# nrf7140_application register map
Vendor: Nordic Semiconductor; Series: nRF71; File version: 1
CPU: CM33 r0p4, little endian, MPU, FPU, 3 interrupt priority bits, 480 interrupts, 8 SAU regions
Registers are 32-bit, read-write, reset 0x0 unless marked. A register's access mark holds for its fields unless they carry their own. Offsets are from the block's base; [hi:lo] are bit positions; lines under a group give offsets from that group; {n}, {i} and the like mark numbered series.

## GLOBAL_P0_NS — GPIO Port 0
Base 0x4F938000
Same registers: GLOBAL_P1_NS 0x4F938200, GLOBAL_P2_NS 0x4F938400, GLOBAL_P3_NS 0x4F938600, GLOBAL_P5_NS 0x4F938A00, GLOBAL_P6_NS 0x4F938C00, GLOBAL_P8_NS 0x4F939000, GLOBAL_P9_NS 0x4F939200, GLOBAL_P0_S 0x5F938000, GLOBAL_P1_S 0x5F938200, GLOBAL_P2_S 0x5F938400, GLOBAL_P3_S 0x5F938600, GLOBAL_P5_S 0x5F938A00, GLOBAL_P6_S 0x5F938C00, GLOBAL_P8_S 0x5F939000, GLOBAL_P9_S 0x5F939200
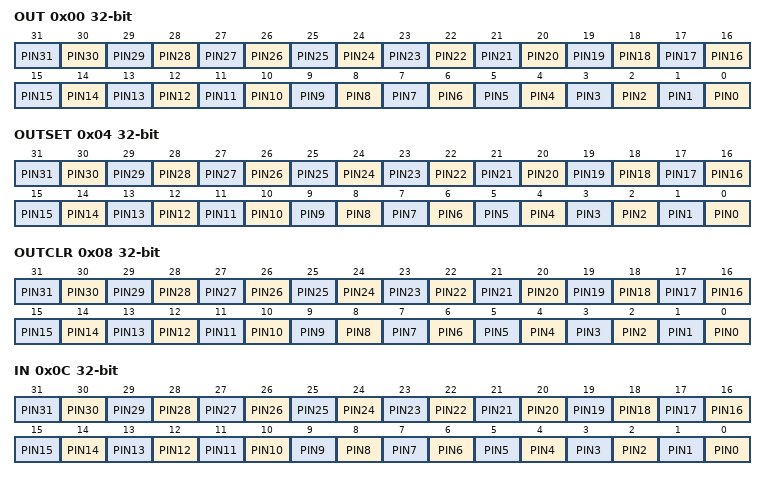
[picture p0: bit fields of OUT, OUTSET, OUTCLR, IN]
0x00 OUT — Write GPIO port
  [all] fields
    0=Low (Pin driver is low); 1=High (Pin driver is high)
  [n] PIN{n} (n=0..31)
0x04 OUTSET write-1-sets — Set individual bits in GPIO port
  [all] fields
    on read: 0=Low (Read: pin driver is low); 1=High (Read: pin driver is high) | on write: 1=Set (Write: writing a '1' sets the pin high; writing a '0' has no effect)
  [n] PIN{n} (n=0..31)
0x08 OUTCLR write-1-clears — Clear individual bits in GPIO port
  [all] fields
    on read: 0=Low (Read: pin driver is low); 1=High (Read: pin driver is high) | on write: 1=Clear (Write: writing a '1' sets the pin low; writing a '0' has no effect)
  [n] PIN{n} (n=0..31)
0x0C IN ro — Read GPIO port
  [all] fields
    0=Low (Pin input is low); 1=High (Pin input is high)
  [n] PIN{n} (n=0..31)
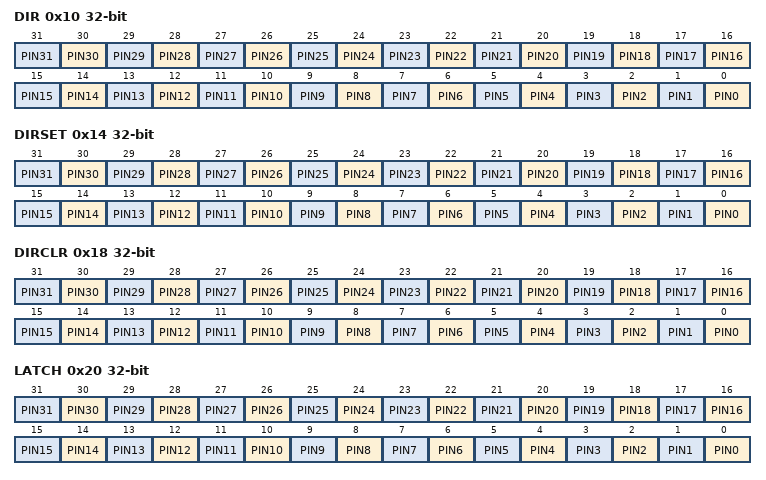
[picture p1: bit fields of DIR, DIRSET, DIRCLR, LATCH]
0x10 DIR — Direction of GPIO pins
  [all] fields
    0=Input (Pin set as input); 1=Output (Pin set as output)
  [n] PIN{n} (n=0..31)
0x14 DIRSET write-1-sets
  [all] fields
    on read: 0=Input (Read: pin set as input); 1=Output (Read: pin set as output) | on write: 1=Set (Write: writing a '1' sets pin to output; writing a '0' has no effect)
  [n] PIN{n} (n=0..31) — Set as output pin {n}
0x18 DIRCLR write-1-clears — DIR clear register
  [all] fields
    on read: 0=Input (Read: pin set as input); 1=Output (Read: pin set as output) | on write: 1=Clear (Write: writing a '1' sets pin to input; writing a '0' has no effect)
  [n] PIN{n} (n=0..31) — Set as input pin {n}
0x20 LATCH — Latch register indicating what GPIO pins that have met the criteria set in the PIN_CNF[n].SENSE registers
  [all] fields
    0=NotLatched (Criteria has not been met); 1=Latched (Criteria has been met)
  [n] PIN{n} (n=0..31) — Status on whether PIN{n} has met criteria set in PIN_CNF[{n}].SENSE register. Write '1' to clear.
0x24 DETECTMODE — Select between default DETECT signal behavior and LDETECT mode
  [0] DETECTMODE
    0=Default (DETECT directly connected to PIN DETECT signals); 1=LDETECT (Use the latched LDETECT behavior)
0x30 PORTCNF group — Unspecified
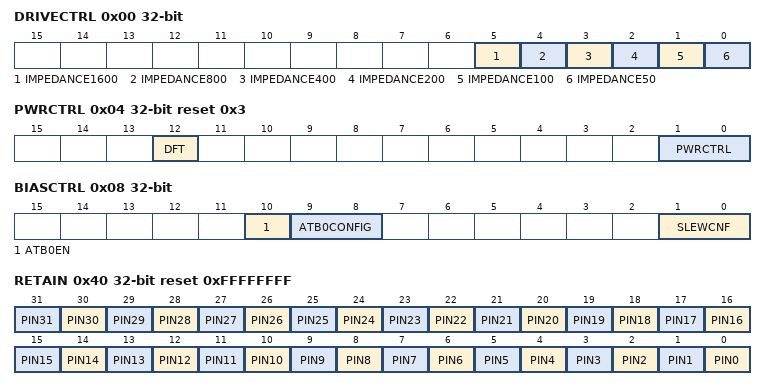
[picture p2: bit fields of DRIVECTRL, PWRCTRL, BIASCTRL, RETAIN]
  0x00 DRIVECTRL — Drive control for impedance matching of the pins in this port
    [all] fields
      0=Disabled; 1=Enable
    [5] IMPEDANCE1600 — Enable 1600 ohms impedance to the pins in this port
    [4] IMPEDANCE800 — Enable 800 ohms impedance to the pins in this port
    [3] IMPEDANCE400 — Enable 400 ohms impedance to the pins in this port
    [2] IMPEDANCE200 — Enable 200 ohms impedance to the pins in this port
    [1] IMPEDANCE100 — Enable 100 ohms impedance to the pins in this port
    [0] IMPEDANCE50 — Enable 50 ohms impedance to the pins in this port
  0x04 PWRCTRL reset 0x3 — Power control of the pins in this port
    [12] DFT — Enable down divided VSS_FLOAT on analog test bus
      0=Disabled; 1=Enable
    [1:0] PWRCTRL — Power control
      0=Off (Power off); 1=FloatingGND0V (Static floating GND of the pin, connected to 0V); 2=FloatingGND1V8 (Static floating GND of the pin, connected to 1.8V); 3=FloatingGNDBuf (Buffered floating GND of the pin, generating VDDIO - 1.8V)
  0x08 BIASCTRL — Configuration of slew rate
    [10] ATB0EN — Enablie the Analog Test Bus
      0=Disabled (Analog test bus disabled); 1=Enabled (Analog test bus enabled)
    [9:8] ATB0CONFIG — Configuration of Analog Test Bus 0
      0=HiZ (Not used); 1=PTAT (Current from PTAT circuit); 2=SUPPLY (Current from supply bias circuit); 3=TRIM (Current from bias after trim)
    [1:0] SLEWCNF — Slew configuration
      0=Freq24 (Frequency range 8MHz to 24MHz); 1=Freq48 (Frequency range 24MHz to 48MHz); 2=Freq72 (Frequency range 48MHz to 72MHz); 3=Freq100 (Frequency range 72MHz to 100MHz)
0x40 RETAIN reset 0xFFFFFFFF — RETAIN of each individual GPIO pin. Pins with their RETAIN bit set keep their state independent of changes of the GPIO-configuration and peripheral changes. RETAIN must be cleared before the pin can be used. RETAIN is typically used to isolate the pin state from internal device state changes. The pin will keep all its state including the output value, DIR and PORTCNF settings.
  [all] fields
    0=Unretained (Pin not retained); 1=Retained (Pin retained)
  [n] PIN{n} (n=0..31)
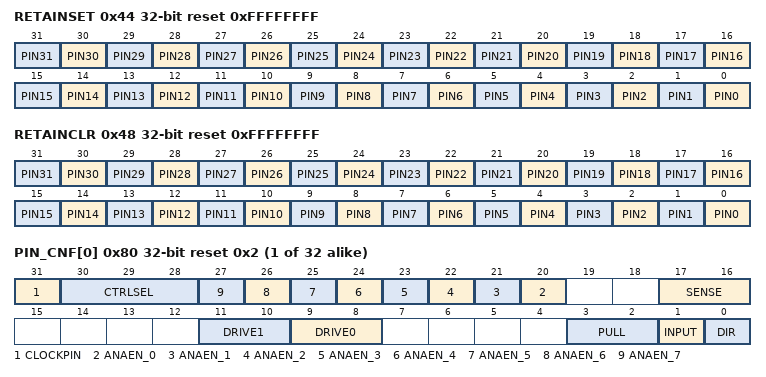
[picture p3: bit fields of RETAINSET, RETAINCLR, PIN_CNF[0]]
0x44 RETAINSET reset 0xFFFFFFFF write-1-sets — Set RETAIN for individual GPIO pins
  [all] fields
    on read: 0=Unretained (Read: pin not retained); 1=Retained (Read: pin retained) | on write: 1=Set (Write: writing a '1' sets pin to retained; writing a '0' has no effect)
  [n] PIN{n} (n=0..31) — Set RETAIN for pin {n}
0x48 RETAINCLR reset 0xFFFFFFFF write-1-clears — Clear RETAIN for individual GPIO pins
  [all] fields
    on read: 0=Unretained (Read: pin not retained); 1=Retained (Read: pin retained) | on write: 1=Clear (Write: writing a '1' sets pin to not retain; writing a '0' has no effect)
  [n] PIN{n} (n=0..31) — Clear RETAIN for pin {n}
{0x80+4i} PIN_CNF[{i}] (i=0..31) reset 0x2 — Description collection: Pin n configuration of GPIO pin
  [31] CLOCKPIN — Enable clock on the pin.
    0=Disabled (Clock disabled); 1=Enabled (Clock enabled)
  [30:28] CTRLSEL — Select which MCU/Subsystem controls this pin
    0=GPIO (GPIO peripheral); 1=VPR (VPR processor); 2=SecureDomain; 2=PWM (PWM peripheral); 3=SDCARD (SDCARD peripheral); 3=Serial (SPIM/SPIS/TWIM/TWIS/UARTE peripheral); 3=HSSPI (High-speed SPI peripheral); 4=Radio Core (DFE GPIO, RXDATA, TXDATA, BBPROC); 4=Wi-Fi Core GPIO; 4=EXMIF (EXMIF peripheral); 4=QSPI (QSPI peripheral); 5=CAN (CAN peripheral); 5=GRC (GRC system); 5=GRTC (GRTC peripheral); 6=DTB (Digital Test Bus); 6=I3C (I3C peripheral); 4=RadioCoreGPIOTE; 7=TND (Trace and Debug Subsystem); 7=TDM (TDM peripheral); 7=SIMIF (SIMIF peripheral); 7=ANTSWC (ANTSWC peripheral); 7=DISPC (Display controller QSPI peripheral)
  [n+20] ANAEN_{n} (n=0..7) — Control of analog slices for pads with ATB functionality. LSB in ANAEN control slice 0, and so on.
    0=Disabled (Slice disabled); 1=Enabled (Slice enabled)
  [17:16] SENSE — Pin sensing mechanism
    0=Disabled; 2=High (Sense for high level); 3=Low (Sense for low level)
  [11:10] DRIVE1 — Drive configuration for '1'
    0=S1 (Standard '1'); 1=H1 (High drive '1'); 2=D1 (Disconnect '1'(normally used for wired-or connections)); 3=E1 (Extra high drive '1')
  [9:8] DRIVE0 — Drive configuration for '0'
    0=S0 (Standard '0'); 1=H0 (High drive '0'); 2=D0 (Disconnect '0'(normally used for wired-or connections)); 3=E0 (Extra high drive '0')
  [3:2] PULL — Pull configuration
    0=Disabled (No pull); 1=Pull down on pin; 3=Pull up on pin
  [1] INPUT — Connect or disconnect input buffer
    0=Connect input buffer; 1=Disconnect input buffer
  [0] DIR — Pin direction. Same physical register as DIR register
    0=Input (Configure pin as an input pin); 1=Output (Configure pin as an output pin)
